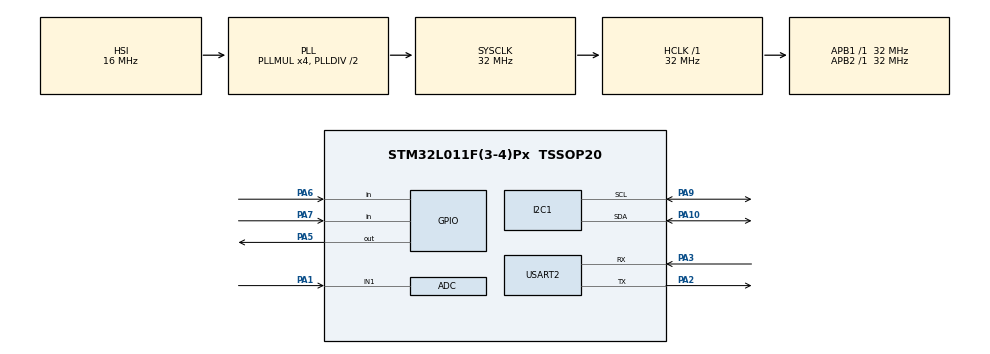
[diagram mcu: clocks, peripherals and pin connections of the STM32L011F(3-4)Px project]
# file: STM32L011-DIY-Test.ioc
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I2C1.Timing=0x00B07CB4
Mcu.Family=STM32L0
Mcu.Name=STM32L011F(3-4)Px
Mcu.Package=TSSOP20
NVIC.ADC1_COMP_IRQn=true\:0\:0\:false\:false\:true\:true\:true\:true
PA1.Mode=IN1
PA1.Signal=ADC_IN1
PA10.Mode=I2C
PA10.Signal=I2C1_SDA
PA2.Mode=Asynchronous
PA2.Signal=USART2_TX
PA3.Mode=Asynchronous
PA3.Signal=USART2_RX
PA5.Signal=GPIO_Output
PA6.Signal=GPIO_Input
PA7.Signal=GPIO_Input
PA9.Mode=I2C
PA9.Signal=I2C1_SCL
ProjectManager.HeapSize=0x200
ProjectManager.StackSize=0x400
ProjectManager.TargetToolchain=STM32CubeIDE
RCC.ADCFreq_Value=16000000
RCC.AHBFreq_Value=32000000
RCC.APB1Freq_Value=32000000
RCC.APB1TimFreq_Value=32000000
RCC.APB2Freq_Value=32000000
RCC.APB2TimFreq_Value=32000000
RCC.HCLKFreq_Value=32000000
RCC.HSE_VALUE=8000000
RCC.HSI16_VALUE=16000000
RCC.HSI_VALUE=16000000
RCC.LSE_VALUE=32768
RCC.MSI_VALUE=2097000
RCC.PLLMUL=RCC_PLLMUL_4
RCC.SYSCLKFreq_VALUE=32000000
RCC.SYSCLKSource=RCC_SYSCLKSOURCE_PLLCLK
RCC.VCOOutputFreq_Value=64000000
USART2.VirtualMode-Asynchronous=VM_ASYNC
board=custom

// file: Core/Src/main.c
/* USER CODE BEGIN Header */
/**
  ******************************************************************************
  * @file           : main.c
  * @brief          : Main program body
  ******************************************************************************
  * @attention
  *
  * Copyright (c) 2025 STMicroelectronics.
  * All rights reserved.
  *
  * This software is licensed under terms that can be found in the LICENSE file
  * in the root directory of this software component.
  * If no LICENSE file comes with this software, it is provided AS-IS.
  *
  ******************************************************************************
  */
/* USER CODE END Header */
#include "main.h"

/* USER CODE BEGIN Includes */
#include "i2c_master_test.h"
#include "adc_test.h"
/* USER CODE END Includes */

ADC_HandleTypeDef hadc;

I2C_HandleTypeDef hi2c1;

UART_HandleTypeDef huart2;

void SystemClock_Config(void);
static void MX_GPIO_Init(void);
static void MX_ADC_Init(void);
static void MX_I2C1_Init(void);
static void MX_USART2_UART_Init(void);

int main(void)
{

  /* MCU Configuration--------------------------------------------------------*/

  /* Reset of all peripherals, Initializes the Flash interface and the Systick. */
  HAL_Init();

  /* Configure the system clock */
  SystemClock_Config();

  /* Initialize all configured peripherals */
  MX_GPIO_Init();
  MX_ADC_Init();
  MX_I2C1_Init();
  MX_USART2_UART_Init();

  /* Infinite loop */
  while (1)
  {

    /* USER CODE BEGIN 3 */
	HAL_Delay(1000);
	adc_test();
  }
  /* USER CODE END 3 */
}

void SystemClock_Config(void)
{
  RCC_OscInitTypeDef RCC_OscInitStruct = {0};
  RCC_ClkInitTypeDef RCC_ClkInitStruct = {0};
  RCC_PeriphCLKInitTypeDef PeriphClkInit = {0};

  /** Configure the main internal regulator output voltage
  */
  __HAL_PWR_VOLTAGESCALING_CONFIG(PWR_REGULATOR_VOLTAGE_SCALE1);

  /** Initializes the RCC Oscillators according to the specified parameters
  * in the RCC_OscInitTypeDef structure.
  */
  RCC_OscInitStruct.OscillatorType = RCC_OSCILLATORTYPE_HSI;
  RCC_OscInitStruct.HSIState = RCC_HSI_ON;
  RCC_OscInitStruct.HSICalibrationValue = RCC_HSICALIBRATION_DEFAULT;
  RCC_OscInitStruct.PLL.PLLState = RCC_PLL_ON;
  RCC_OscInitStruct.PLL.PLLSource = RCC_PLLSOURCE_HSI;
  RCC_OscInitStruct.PLL.PLLMUL = RCC_PLLMUL_4;
  RCC_OscInitStruct.PLL.PLLDIV = RCC_PLLDIV_2;
  if (HAL_RCC_OscConfig(&RCC_OscInitStruct) != HAL_OK)
  {
    Error_Handler();
  }

  /** Initializes the CPU, AHB and APB buses clocks
  */
  RCC_ClkInitStruct.ClockType = RCC_CLOCKTYPE_HCLK|RCC_CLOCKTYPE_SYSCLK
                              |RCC_CLOCKTYPE_PCLK1|RCC_CLOCKTYPE_PCLK2;
  RCC_ClkInitStruct.SYSCLKSource = RCC_SYSCLKSOURCE_PLLCLK;
  RCC_ClkInitStruct.AHBCLKDivider = RCC_SYSCLK_DIV1;
  RCC_ClkInitStruct.APB1CLKDivider = RCC_HCLK_DIV1;
  RCC_ClkInitStruct.APB2CLKDivider = RCC_HCLK_DIV1;

  if (HAL_RCC_ClockConfig(&RCC_ClkInitStruct, FLASH_LATENCY_1) != HAL_OK)
  {
    Error_Handler();
  }
  PeriphClkInit.PeriphClockSelection = RCC_PERIPHCLK_USART2|RCC_PERIPHCLK_I2C1;
  PeriphClkInit.Usart2ClockSelection = RCC_USART2CLKSOURCE_PCLK1;
  PeriphClkInit.I2c1ClockSelection = RCC_I2C1CLKSOURCE_PCLK1;
  if (HAL_RCCEx_PeriphCLKConfig(&PeriphClkInit) != HAL_OK)
  {
    Error_Handler();
  }
}

static void MX_ADC_Init(void)
{

  ADC_ChannelConfTypeDef sConfig = {0};

  /** Configure the global features of the ADC (Clock, Resolution, Data Alignment and number of conversion)
  */
  hadc.Instance = ADC1;
  hadc.Init.OversamplingMode = DISABLE;
  hadc.Init.ClockPrescaler = ADC_CLOCK_SYNC_PCLK_DIV2;
  hadc.Init.Resolution = ADC_RESOLUTION_12B;
  hadc.Init.SamplingTime = ADC_SAMPLETIME_1CYCLE_5;
  hadc.Init.ScanConvMode = ADC_SCAN_DIRECTION_FORWARD;
  hadc.Init.DataAlign = ADC_DATAALIGN_RIGHT;
  hadc.Init.ContinuousConvMode = DISABLE;
  hadc.Init.DiscontinuousConvMode = DISABLE;
  hadc.Init.ExternalTrigConvEdge = ADC_EXTERNALTRIGCONVEDGE_NONE;
  hadc.Init.ExternalTrigConv = ADC_SOFTWARE_START;
  hadc.Init.DMAContinuousRequests = DISABLE;
  hadc.Init.EOCSelection = ADC_EOC_SINGLE_CONV;
  hadc.Init.Overrun = ADC_OVR_DATA_PRESERVED;
  hadc.Init.LowPowerAutoWait = DISABLE;
  hadc.Init.LowPowerFrequencyMode = DISABLE;
  hadc.Init.LowPowerAutoPowerOff = DISABLE;
  if (HAL_ADC_Init(&hadc) != HAL_OK)
  {
    Error_Handler();
  }

  /** Configure for the selected ADC regular channel to be converted.
  */
  sConfig.Channel = ADC_CHANNEL_1;
  sConfig.Rank = ADC_RANK_CHANNEL_NUMBER;
  if (HAL_ADC_ConfigChannel(&hadc, &sConfig) != HAL_OK)
  {
    Error_Handler();
  }

}

static void MX_I2C1_Init(void)
{

  hi2c1.Instance = I2C1;
  hi2c1.Init.Timing = 0x00B07CB4;
  hi2c1.Init.OwnAddress1 = 0;
  hi2c1.Init.AddressingMode = I2C_ADDRESSINGMODE_7BIT;
  hi2c1.Init.DualAddressMode = I2C_DUALADDRESS_DISABLE;
  hi2c1.Init.OwnAddress2 = 0;
  hi2c1.Init.OwnAddress2Masks = I2C_OA2_NOMASK;
  hi2c1.Init.GeneralCallMode = I2C_GENERALCALL_DISABLE;
  hi2c1.Init.NoStretchMode = I2C_NOSTRETCH_DISABLE;
  if (HAL_I2C_Init(&hi2c1) != HAL_OK)
  {
    Error_Handler();
  }

  /** Configure Analogue filter
  */
  if (HAL_I2CEx_ConfigAnalogFilter(&hi2c1, I2C_ANALOGFILTER_ENABLE) != HAL_OK)
  {
    Error_Handler();
  }

  /** Configure Digital filter
  */
  if (HAL_I2CEx_ConfigDigitalFilter(&hi2c1, 0) != HAL_OK)
  {
    Error_Handler();
  }

}

static void MX_USART2_UART_Init(void)
{

  huart2.Instance = USART2;
  huart2.Init.BaudRate = 115200;
  huart2.Init.WordLength = UART_WORDLENGTH_8B;
  huart2.Init.StopBits = UART_STOPBITS_1;
  huart2.Init.Parity = UART_PARITY_NONE;
  huart2.Init.Mode = UART_MODE_TX_RX;
  huart2.Init.HwFlowCtl = UART_HWCONTROL_NONE;
  huart2.Init.OverSampling = UART_OVERSAMPLING_16;
  huart2.Init.OneBitSampling = UART_ONE_BIT_SAMPLE_DISABLE;
  huart2.AdvancedInit.AdvFeatureInit = UART_ADVFEATURE_NO_INIT;
  if (HAL_UART_Init(&huart2) != HAL_OK)
  {
    Error_Handler();
  }

}

static void MX_GPIO_Init(void)
{
  GPIO_InitTypeDef GPIO_InitStruct = {0};

  /* GPIO Ports Clock Enable */
  __HAL_RCC_GPIOA_CLK_ENABLE();

  /*Configure GPIO pin Output Level */
  HAL_GPIO_WritePin(GPIOA, GPIO_PIN_5, GPIO_PIN_RESET);

  /*Configure GPIO pin : PA5 */
  GPIO_InitStruct.Pin = GPIO_PIN_5;
  GPIO_InitStruct.Mode = GPIO_MODE_OUTPUT_PP;
  GPIO_InitStruct.Pull = GPIO_NOPULL;
  GPIO_InitStruct.Speed = GPIO_SPEED_FREQ_LOW;
  HAL_GPIO_Init(GPIOA, &GPIO_InitStruct);

  /*Configure GPIO pins : PA6 PA7 */
  GPIO_InitStruct.Pin = GPIO_PIN_6|GPIO_PIN_7;
  GPIO_InitStruct.Mode = GPIO_MODE_INPUT;
  GPIO_InitStruct.Pull = GPIO_NOPULL;
  HAL_GPIO_Init(GPIOA, &GPIO_InitStruct);

}

void Error_Handler(void)
{
  __disable_irq();
  while (1)
  {
  }
}
